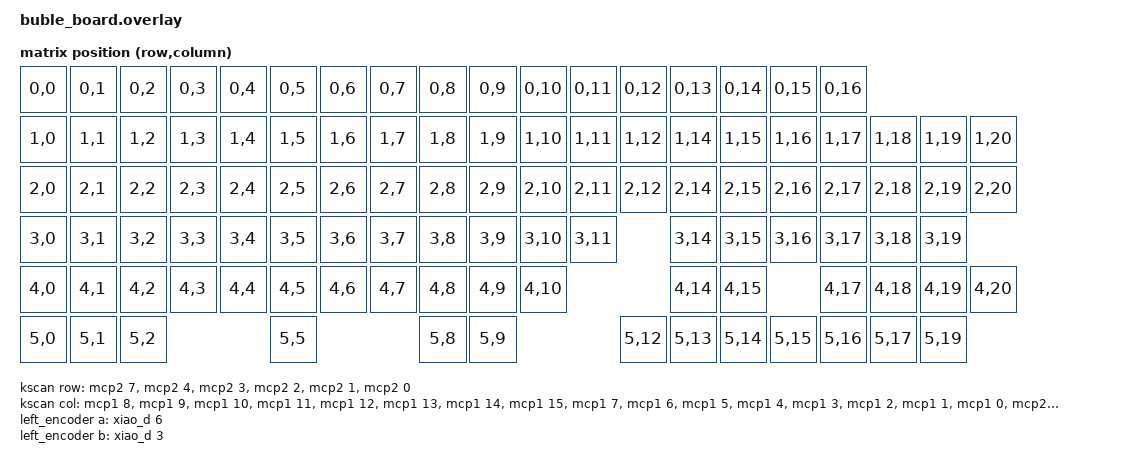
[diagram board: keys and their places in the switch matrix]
// This file was generated from a template. Edit it to match your keyboard.
// See https://zmk.dev/docs/development/hardware-integration/new-shield for more
// instructions.

#include <dt-bindings/zmk/matrix_transform.h>

#include "buble_board-layouts.dtsi"

/ {
    chosen {
        zmk,physical-layout = &default_layout;
    };

    kscan: kscan {
        // If the hardware does not use a switch matrix, change this to the
        // appropriate driver and update the properties below to match.
        // See https://zmk.dev/docs/config/kscan for supported key scan drivers.
        compatible = "zmk,kscan-gpio-matrix";
        // compatible = "zmk,kscan-gpio-direct";
        // Set this to "col2row" or "row2col" to match the hardware. If using
        // "row2col", change the col-gpios to (GPIO_ACTIVE_HIGH | GPIO_PULL_DOWN)
        // and the row-gpios to GPIO_ACTIVE_HIGH.
        diode-direction = "row2col";
        wakeup-source;

        // Replace these comments with the GPIO pins in the matrix.
        // See https://zmk.dev/docs/development/hardware-integration/new-shield#shield-overlays
        col-gpios
            = <&mcp1 8 (GPIO_ACTIVE_LOW | GPIO_PULL_UP)>    // Column 0
            , <&mcp1 9 (GPIO_ACTIVE_LOW | GPIO_PULL_UP)>    // Column 1
            , <&mcp1 10 (GPIO_ACTIVE_LOW | GPIO_PULL_UP)>   // Column 2
            , <&mcp1 11 (GPIO_ACTIVE_LOW | GPIO_PULL_UP)>   // Column 3
            , <&mcp1 12 (GPIO_ACTIVE_LOW | GPIO_PULL_UP)>   // Column 4
            , <&mcp1 13 (GPIO_ACTIVE_LOW | GPIO_PULL_UP)>   // Column 5
            , <&mcp1 14 (GPIO_ACTIVE_LOW | GPIO_PULL_UP)>   // Column 6
            , <&mcp1 15 (GPIO_ACTIVE_LOW | GPIO_PULL_UP)>   // Column 7
            , <&mcp1 7 (GPIO_ACTIVE_LOW | GPIO_PULL_UP)>    // Column 8
            , <&mcp1 6 (GPIO_ACTIVE_LOW | GPIO_PULL_UP)>    // Column 9
            , <&mcp1 5 (GPIO_ACTIVE_LOW | GPIO_PULL_UP)>    // Column 10
            , <&mcp1 4 (GPIO_ACTIVE_LOW | GPIO_PULL_UP)>    // Column 11
            , <&mcp1 3 (GPIO_ACTIVE_LOW | GPIO_PULL_UP)>    // Column 12
            , <&mcp1 2 (GPIO_ACTIVE_LOW | GPIO_PULL_UP)>    // Column 13
            , <&mcp1 1 (GPIO_ACTIVE_LOW | GPIO_PULL_UP)>    // Column 14
            , <&mcp1 0 (GPIO_ACTIVE_LOW | GPIO_PULL_UP)>    // Column 15
            , <&mcp2 12 (GPIO_ACTIVE_LOW | GPIO_PULL_UP)>   // Column 16
            , <&mcp2 11 (GPIO_ACTIVE_LOW | GPIO_PULL_UP)>   // Column 17
            , <&mcp2 10 (GPIO_ACTIVE_LOW | GPIO_PULL_UP)>   // Column 18
            , <&mcp2 9 (GPIO_ACTIVE_LOW | GPIO_PULL_UP)>    // Column 19
            , <&mcp2 8 (GPIO_ACTIVE_LOW | GPIO_PULL_UP)>    // Column 20
            ;

        row-gpios
            = <&mcp2 7 GPIO_ACTIVE_LOW> // Row 0
            , <&mcp2 4 GPIO_ACTIVE_LOW> // Row 1
            , <&mcp2 3 GPIO_ACTIVE_LOW> // Row 2
            , <&mcp2 2 GPIO_ACTIVE_LOW> // Row 3
            , <&mcp2 1 GPIO_ACTIVE_LOW> // Row 4
            , <&mcp2 0 GPIO_ACTIVE_LOW> // Row 5
            ;

        //input-gpios
        //      = <&mcp2 7 (GPIO_ACTIVE_LOW | GPIO_PULL_UP)>
        //      , <&mcp1 8 (GPIO_ACTIVE_LOW | GPIO_PULL_UP)>
        //      , <&mcp2 3 (GPIO_ACTIVE_LOW | GPIO_PULL_UP)>
        //      , <&mcp2 2 (GPIO_ACTIVE_LOW | GPIO_PULL_UP)>
        //      ;
    };

    default_transform: default_transform {
        // See https://zmk.dev/docs/development/hardware-integration/new-shield#matrix-transform
        // for how to configure this
        compatible = "zmk,matrix-transform";
        columns = <21>;
        rows = <6>;

        map = <
            RC(0, 0) RC(0, 1) RC(0, 2) RC(0, 3) RC(0, 4) RC(0, 5) RC(0, 6) RC(0, 7) RC(0, 8) RC(0, 9) RC(0, 10) RC(0, 11) RC(0, 12) RC(0, 13) RC(0, 14) RC(0, 15) RC(0, 16)
            RC(1, 0) RC(1, 1) RC(1, 2) RC(1, 3) RC(1, 4) RC(1, 5) RC(1, 6) RC(1, 7) RC(1, 8) RC(1, 9) RC(1, 10) RC(1, 11) RC(1, 12)           RC(1, 14) RC(1, 15) RC(1, 16) RC(1, 17) RC(1, 18) RC(1, 19) RC(1, 20)
            RC(2, 0) RC(2, 1) RC(2, 2) RC(2, 3) RC(2, 4) RC(2, 5) RC(2, 6) RC(2, 7) RC(2, 8) RC(2, 9) RC(2, 10) RC(2, 11) RC(2, 12)           RC(2, 14) RC(2, 15) RC(2, 16) RC(2, 17) RC(2, 18) RC(2, 19) RC(2, 20)
            RC(3, 0) RC(3, 1) RC(3, 2) RC(3, 3) RC(3, 4) RC(3, 5) RC(3, 6) RC(3, 7) RC(3, 8) RC(3, 9) RC(3, 10) RC(3, 11)                     RC(3, 14) RC(3, 15) RC(3, 16) RC(3, 17) RC(3, 18) RC(3, 19)
            RC(4, 0) RC(4, 1) RC(4, 2) RC(4, 3) RC(4, 4) RC(4, 5) RC(4, 6) RC(4, 7) RC(4, 8) RC(4, 9) RC(4, 10)                               RC(4, 14) RC(4, 15)           RC(4, 17) RC(4, 18) RC(4, 19) RC(4, 20)
            RC(5, 0) RC(5, 1) RC(5, 2)                   RC(5, 5)                   RC(5, 8) RC(5, 9)                     RC(5, 12) RC(5, 13) RC(5, 14) RC(5, 15) RC(5, 16) RC(5, 17)           RC(5, 19)
        >;
    };

    left_encoder: encoder_left {
        compatible = "alps,ec11";
        label = "encoder";
        a-gpios = <&xiao_d 6 (GPIO_ACTIVE_HIGH | GPIO_PULL_UP)>;
        b-gpios = <&xiao_d 3 (GPIO_ACTIVE_HIGH | GPIO_PULL_UP)>;
        steps = <80>;
        status = "okay";
    };

    sensors: sensors {
        compatible = "zmk,keymap-sensors";
        sensors = <&left_encoder>;
    };
};

&xiao_i2c {
    status = "okay";
    clock-frequency = <I2C_BITRATE_FAST>;

    mcp1: mcp23017@24 {
        compatible = "microchip,mcp230xx";
        status = "okay";
        gpio-controller;
        wakeup-source;
        reg = <0x24>;
        #gpio-cells = <2>;
        ngpios = <16>;
        int-gpios = <&xiao_d 1 (GPIO_ACTIVE_LOW | GPIO_PULL_UP)>;
    };

    mcp2: mcp23017@20 {
        compatible = "microchip,mcp230xx";
        status = "okay";
        gpio-controller;
        wakeup-source;
        reg = <0x20>;
        #gpio-cells = <2>;
        ngpios = <16>;
        int-gpios = <&xiao_d 0 (GPIO_ACTIVE_LOW | GPIO_PULL_UP)>;
    };
};

nice_view_spi: &xiao_spi {
    cs-gpios = <&xiao_d 2 GPIO_ACTIVE_HIGH>;
};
